AUTOSAR XML (schema 4-2-1)
package /RootP_IntDcm
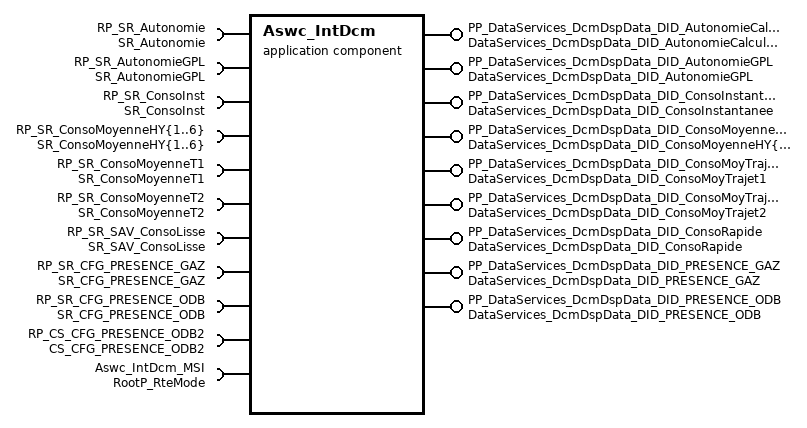
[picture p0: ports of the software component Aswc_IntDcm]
  application sw component type Aswc_IntDcm
    14 x provide port:
      PP_DataServices_DcmDspData_DID_AutonomieCalculee: server-com-spec{operation=DataServices_DcmDspData_DID_AutonomieCalculee/ReadData, queue-length=1}, provided-interface=DataServices_DcmDspData_DID_AutonomieCalculee
      PP_DataServices_DcmDspData_DID_AutonomieGPL: server-com-spec{operation=DataServices_DcmDspData_DID_AutonomieGPL/ReadData, queue-length=1}, provided-interface=DataServices_DcmDspData_DID_AutonomieGPL
      PP_DataServices_DcmDspData_DID_ConsoInstantanee: server-com-spec{operation=DataServices_DcmDspData_DID_ConsoInstantanee/ReadData, queue-length=1}, provided-interface=DataServices_DcmDspData_DID_ConsoInstantanee
      PP_DataServices_DcmDspData_DID_ConsoMoyenneHY{1..6}: server-com-spec{operation=DataServices_DcmDspData_DID_ConsoMoyenneHY{1..6}/ReadData, queue-length=1}, provided-interface=DataServices_DcmDspData_DID_ConsoMoyenneHY{1..6}
      PP_DataServices_DcmDspData_DID_ConsoMoyTrajet1: server-com-spec{operation=DataServices_DcmDspData_DID_ConsoMoyTrajet1/ReadData, queue-length=1}, provided-interface=DataServices_DcmDspData_DID_ConsoMoyTrajet1
      PP_DataServices_DcmDspData_DID_ConsoMoyTrajet2: server-com-spec{operation=DataServices_DcmDspData_DID_ConsoMoyTrajet2/ReadData, queue-length=1}, provided-interface=DataServices_DcmDspData_DID_ConsoMoyTrajet2
      PP_DataServices_DcmDspData_DID_ConsoRapide: server-com-spec{operation=DataServices_DcmDspData_DID_ConsoRapide/ReadData, queue-length=1}, provided-interface=DataServices_DcmDspData_DID_ConsoRapide
      PP_DataServices_DcmDspData_DID_PRESENCE_GAZ: provided-interface=DataServices_DcmDspData_DID_PRESENCE_GAZ
        provided-com-specs:
          operation=DataServices_DcmDspData_DID_PRESENCE_GAZ/ReadData, queue-length=1
          operation=DataServices_DcmDspData_DID_PRESENCE_GAZ/WriteData, queue-length=1
      PP_DataServices_DcmDspData_DID_PRESENCE_ODB: provided-interface=DataServices_DcmDspData_DID_PRESENCE_ODB
        provided-com-specs:
          operation=DataServices_DcmDspData_DID_PRESENCE_ODB/ReadData, queue-length=1
          operation=DataServices_DcmDspData_DID_PRESENCE_ODB/WriteData, queue-length=1
    provide/require port PP_SR_CFG_PRESENCE_GAZ: provided-required-interface=SR_CFG_PRESENCE_GAZ
    provide/require port PP_SR_CFG_PRESENCE_ODB: provided-required-interface=SR_CFG_PRESENCE_ODB
    16 x require port:
      RP_SR_Autonomie: required-interface=SR_Autonomie
      RP_SR_AutonomieGPL: required-interface=SR_AutonomieGPL
      RP_SR_ConsoInst: required-interface=SR_ConsoInst
      RP_SR_ConsoMoyenneHY{1..6}: required-interface=SR_ConsoMoyenneHY{1..6}
      RP_SR_ConsoMoyenneT1: required-interface=SR_ConsoMoyenneT1
      RP_SR_ConsoMoyenneT2: required-interface=SR_ConsoMoyenneT2
      RP_SR_SAV_ConsoLisse: required-interface=SR_SAV_ConsoLisse
      RP_SR_CFG_PRESENCE_GAZ: required-interface=SR_CFG_PRESENCE_GAZ
      RP_SR_CFG_PRESENCE_ODB: required-interface=SR_CFG_PRESENCE_ODB
      RP_CS_CFG_PRESENCE_ODB2: required-interface=CS_CFG_PRESENCE_ODB2
      Aswc_IntDcm_MSI: required-interface=RootP_RteMode
    behavior IB_Aswc_IntDcm: data-type-mapping=ApplicationModeMapping, handle-termination-and-restart=NO-SUPPORT
      16 x operation invoked event:
        DataServices_DcmDspData_DID_AutonomieCalculee_ReadData_OIE: start-on-event=RUNS_DID_AutonomieCalculee_Get, operation=PP_DataServices_DcmDspData_DID_AutonomieCalculee.ReadData
        DataServices_DcmDspData_DID_AutonomieGPL_ReadData_OIE: start-on-event=RUNS_DID_AutonomieGPL_Get, operation=PP_DataServices_DcmDspData_DID_AutonomieGPL.ReadData
        DataServices_DcmDspData_DID_ConsoInstantanee_ReadData_OIE: start-on-event=RUNS_DID_ConsoInstantanee_Get, operation=PP_DataServices_DcmDspData_DID_ConsoInstantanee.ReadData
        DataServices_DcmDspData_DID_ConsoMoyenneHY{1..6}_ReadData_OIE: start-on-event=RUNS_DID_ConsoMoyenneHY{1..6}_Get, operation=PP_DataServices_DcmDspData_DID_ConsoMoyenneHY{1..6}.ReadData
        DataServices_DcmDspData_DID_ConsoMoyTrajet1_ReadData_OIE: start-on-event=RUNS_DID_ConsoMoyTrajet1_Get, operation=PP_DataServices_DcmDspData_DID_ConsoMoyTrajet1.ReadData
        DataServices_DcmDspData_DID_ConsoMoyTrajet2_ReadData_OIE: start-on-event=RUNS_DID_ConsoMoyTrajet2_Get, operation=PP_DataServices_DcmDspData_DID_ConsoMoyTrajet2.ReadData
        DataServices_DcmDspData_DID_ConsoRapide_ReadData_OIE: start-on-event=RUNS_DID_ConsoRapide_Get, operation=PP_DataServices_DcmDspData_DID_ConsoRapide.ReadData
        DataServices_DcmDspData_DID_PRESENCE_GAZ_ReadData_OIE: start-on-event=RUNS_DID_PRESENCE_GAZ_Get, operation=PP_DataServices_DcmDspData_DID_PRESENCE_GAZ.ReadData
        DataServices_DcmDspData_DID_PRESENCE_GAZ_WriteData_OIE: start-on-event=RUNS_DID_PRESENCE_GAZ_Set, operation=PP_DataServices_DcmDspData_DID_PRESENCE_GAZ.WriteData
        DataServices_DcmDspData_DID_PRESENCE_ODB_ReadData_OIE: start-on-event=RUNS_DID_PRESENCE_ODB_Get, operation=PP_DataServices_DcmDspData_DID_PRESENCE_ODB.ReadData
        DataServices_DcmDspData_DID_PRESENCE_ODB_WriteData_OIE: start-on-event=RUNS_DID_PRESENCE_ODB_Set, operation=PP_DataServices_DcmDspData_DID_PRESENCE_ODB.WriteData
      swc mode switch event RUNPI_Aswc_IntDcm_ENTRY: start-on-event=RUNPI_Aswc_IntDcm, activation=ON-ENTRY, mode=Aswc_IntDcm_MSI.RteMode.APP_WAKEUP
      17 x runnable:
        RUNS_DID_AutonomieCalculee_Get
          data-read-access:
            access dra_Autonomie: accessed-variable=RP_SR_Autonomie.Autonomie
        RUNS_DID_AutonomieGPL_Get
          data-read-access:
            access dra_Autonomie: accessed-variable=RP_SR_Autonomie.Autonomie
            access dra_AutonomieGPL: accessed-variable=RP_SR_AutonomieGPL.AutonomieGPL
        RUNS_DID_ConsoInstantanee_Get
          data-read-access:
            access dra_Autonomie: accessed-variable=RP_SR_Autonomie.Autonomie
            access dra_AutonomieGPL: accessed-variable=RP_SR_AutonomieGPL.AutonomieGPL
            access dra_ConsoInst: accessed-variable=RP_SR_ConsoInst.ConsoInst
        RUNS_DID_ConsoMoyenneHY1_Get
          data-read-access:
            4 x access:
              dra_Autonomie: accessed-variable=RP_SR_Autonomie.Autonomie
              dra_AutonomieGPL: accessed-variable=RP_SR_AutonomieGPL.AutonomieGPL
              dra_ConsoInst: accessed-variable=RP_SR_ConsoInst.ConsoInst
              dra_ConsoMoyenneHY1: accessed-variable=RP_SR_ConsoMoyenneHY1.ConsoMoyenneHY1
        RUNS_DID_ConsoMoyenneHY2_Get
          data-read-access:
            5 x access:
              dra_Autonomie: accessed-variable=RP_SR_Autonomie.Autonomie
              dra_AutonomieGPL: accessed-variable=RP_SR_AutonomieGPL.AutonomieGPL
              dra_ConsoInst: accessed-variable=RP_SR_ConsoInst.ConsoInst
              dra_ConsoMoyenneHY1: accessed-variable=RP_SR_ConsoMoyenneHY1.ConsoMoyenneHY1
              dra_ConsoMoyenneHY2: accessed-variable=RP_SR_ConsoMoyenneHY2.ConsoMoyenneHY2
        RUNS_DID_ConsoMoyenneHY3_Get
          data-read-access:
            6 x access:
              dra_Autonomie: accessed-variable=RP_SR_Autonomie.Autonomie
              dra_AutonomieGPL: accessed-variable=RP_SR_AutonomieGPL.AutonomieGPL
              dra_ConsoInst: accessed-variable=RP_SR_ConsoInst.ConsoInst
              dra_ConsoMoyenneHY{1..3}: accessed-variable=RP_SR_ConsoMoyenneHY{1..3}.ConsoMoyenneHY{1..3}
        RUNS_DID_ConsoMoyenneHY4_Get
          data-read-access:
            7 x access:
              dra_Autonomie: accessed-variable=RP_SR_Autonomie.Autonomie
              dra_AutonomieGPL: accessed-variable=RP_SR_AutonomieGPL.AutonomieGPL
              dra_ConsoInst: accessed-variable=RP_SR_ConsoInst.ConsoInst
              dra_ConsoMoyenneHY{1..4}: accessed-variable=RP_SR_ConsoMoyenneHY{1..4}.ConsoMoyenneHY{1..4}
        RUNS_DID_ConsoMoyenneHY5_Get
          data-read-access:
            8 x access:
              dra_Autonomie: accessed-variable=RP_SR_Autonomie.Autonomie
              dra_AutonomieGPL: accessed-variable=RP_SR_AutonomieGPL.AutonomieGPL
              dra_ConsoInst: accessed-variable=RP_SR_ConsoInst.ConsoInst
              dra_ConsoMoyenneHY{1..5}: accessed-variable=RP_SR_ConsoMoyenneHY{1..5}.ConsoMoyenneHY{1..5}
        RUNS_DID_ConsoMoyenneHY6_Get
          data-read-access:
            9 x access:
              dra_Autonomie: accessed-variable=RP_SR_Autonomie.Autonomie
              dra_AutonomieGPL: accessed-variable=RP_SR_AutonomieGPL.AutonomieGPL
              dra_ConsoInst: accessed-variable=RP_SR_ConsoInst.ConsoInst
              dra_ConsoMoyenneHY{1..6}: accessed-variable=RP_SR_ConsoMoyenneHY{1..6}.ConsoMoyenneHY{1..6}
        RUNS_DID_ConsoMoyTrajet1_Get
          data-read-access:
            10 x access:
              dra_Autonomie: accessed-variable=RP_SR_Autonomie.Autonomie
              dra_AutonomieGPL: accessed-variable=RP_SR_AutonomieGPL.AutonomieGPL
              dra_ConsoInst: accessed-variable=RP_SR_ConsoInst.ConsoInst
              dra_ConsoMoyenneHY{1..6}: accessed-variable=RP_SR_ConsoMoyenneHY{1..6}.ConsoMoyenneHY{1..6}
              dra_ConsoMoyenneT1: accessed-variable=RP_SR_ConsoMoyenneT1.ConsoMoyenneT1
        RUNS_DID_ConsoMoyTrajet2_Get
          data-read-access:
            11 x access:
              dra_Autonomie: accessed-variable=RP_SR_Autonomie.Autonomie
              dra_AutonomieGPL: accessed-variable=RP_SR_AutonomieGPL.AutonomieGPL
              dra_ConsoInst: accessed-variable=RP_SR_ConsoInst.ConsoInst
              dra_ConsoMoyenneHY{1..6}: accessed-variable=RP_SR_ConsoMoyenneHY{1..6}.ConsoMoyenneHY{1..6}
              dra_ConsoMoyenneT1: accessed-variable=RP_SR_ConsoMoyenneT1.ConsoMoyenneT1
              dra_ConsoMoyenneT2: accessed-variable=RP_SR_ConsoMoyenneT2.ConsoMoyenneT2
        RUNS_DID_ConsoRapide_Get
          data-read-access:
            12 x access:
              dra_Autonomie: accessed-variable=RP_SR_Autonomie.Autonomie
              dra_AutonomieGPL: accessed-variable=RP_SR_AutonomieGPL.AutonomieGPL
              dra_ConsoInst: accessed-variable=RP_SR_ConsoInst.ConsoInst
              dra_ConsoMoyenneHY{1..6}: accessed-variable=RP_SR_ConsoMoyenneHY{1..6}.ConsoMoyenneHY{1..6}
              dra_ConsoMoyenneT1: accessed-variable=RP_SR_ConsoMoyenneT1.ConsoMoyenneT1
              dra_ConsoMoyenneT2: accessed-variable=RP_SR_ConsoMoyenneT2.ConsoMoyenneT2
              dra_SAV_ConsoLisse: accessed-variable=RP_SR_SAV_ConsoLisse.SAV_ConsoLisse
        RUNS_DID_PRESENCE_GAZ_Get
          data-read-access:
            13 x access:
              dra_Autonomie: accessed-variable=RP_SR_Autonomie.Autonomie
              dra_AutonomieGPL: accessed-variable=RP_SR_AutonomieGPL.AutonomieGPL
              dra_ConsoInst: accessed-variable=RP_SR_ConsoInst.ConsoInst
              dra_ConsoMoyenneHY{1..6}: accessed-variable=RP_SR_ConsoMoyenneHY{1..6}.ConsoMoyenneHY{1..6}
              dra_ConsoMoyenneT1: accessed-variable=RP_SR_ConsoMoyenneT1.ConsoMoyenneT1
              dra_ConsoMoyenneT2: accessed-variable=RP_SR_ConsoMoyenneT2.ConsoMoyenneT2
              dra_SAV_ConsoLisse: accessed-variable=RP_SR_SAV_ConsoLisse.SAV_ConsoLisse
              dra_CFG_PRESENCE_GAZ: accessed-variable=RP_SR_CFG_PRESENCE_GAZ.CFG_PRESENCE_GAZ
        RUNS_DID_PRESENCE_GAZ_Set
          data-read-access:
            access dra_CFG_PRESENCE_GAZ: accessed-variable=PP_SR_CFG_PRESENCE_GAZ.CFG_PRESENCE_GAZ
          data-write-access:
            access dwa_CFG_PRESENCE_GAZ: accessed-variable=PP_SR_CFG_PRESENCE_GAZ.CFG_PRESENCE_GAZ
        RUNS_DID_PRESENCE_ODB_Get
          data-read-access:
            14 x access:
              dra_Autonomie: accessed-variable=RP_SR_Autonomie.Autonomie
              dra_AutonomieGPL: accessed-variable=RP_SR_AutonomieGPL.AutonomieGPL
              dra_ConsoInst: accessed-variable=RP_SR_ConsoInst.ConsoInst
              dra_ConsoMoyenneHY{1..6}: accessed-variable=RP_SR_ConsoMoyenneHY{1..6}.ConsoMoyenneHY{1..6}
              dra_ConsoMoyenneT1: accessed-variable=RP_SR_ConsoMoyenneT1.ConsoMoyenneT1
              dra_ConsoMoyenneT2: accessed-variable=RP_SR_ConsoMoyenneT2.ConsoMoyenneT2
              dra_SAV_ConsoLisse: accessed-variable=RP_SR_SAV_ConsoLisse.SAV_ConsoLisse
              dra_CFG_PRESENCE_GAZ: accessed-variable=RP_SR_CFG_PRESENCE_GAZ.CFG_PRESENCE_GAZ
              dra_CFG_PRESENCE_ODB: accessed-variable=RP_SR_CFG_PRESENCE_ODB.CFG_PRESENCE_ODB
        RUNS_DID_PRESENCE_ODB_Set
          data-read-access:
            access dra_CFG_PRESENCE_GAZ: accessed-variable=PP_SR_CFG_PRESENCE_GAZ.CFG_PRESENCE_GAZ
            access dra_CFG_PRESENCE_ODB: accessed-variable=PP_SR_CFG_PRESENCE_ODB.CFG_PRESENCE_ODB
          data-write-access:
            access dwa_CFG_PRESENCE_GAZ: accessed-variable=PP_SR_CFG_PRESENCE_GAZ.CFG_PRESENCE_GAZ
            access dwa_CFG_PRESENCE_ODB: accessed-variable=PP_SR_CFG_PRESENCE_ODB.CFG_PRESENCE_ODB
        RUNPI_Aswc_IntDcm
package /AUTOSAR_Dcm/PortInterfaces
  14 x client server interface, all with is-service=true:
    DataServices_DcmDspData_DID_AutonomieCalculee
      operation ReadData
        arg Data: type=tBYTE, direction=OUT
    DataServices_DcmDspData_DID_AutonomieGPL
      operation ReadData
        arg Data: type=tBYTE, direction=OUT
    DataServices_DcmDspData_DID_ConsoInstantanee
      operation ReadData
        arg Data: type=tBYTE, direction=OUT
    DataServices_DcmDspData_DID_ConsoMoyenneHY1
      operation ReadData
        arg Data: type=tBYTE, direction=OUT
    DataServices_DcmDspData_DID_ConsoMoyenneHY2
      operation ReadData
        arg Data: type=tBYTE, direction=OUT
    DataServices_DcmDspData_DID_ConsoMoyenneHY3
      operation ReadData
        arg Data: type=tBYTE, direction=OUT
    DataServices_DcmDspData_DID_ConsoMoyenneHY4
      operation ReadData
        arg Data: type=tBYTE, direction=OUT
    DataServices_DcmDspData_DID_ConsoMoyenneHY5
      operation ReadData
        arg Data: type=tBYTE, direction=OUT
    DataServices_DcmDspData_DID_ConsoMoyenneHY6
      operation ReadData
        arg Data: type=tBYTE, direction=OUT
    DataServices_DcmDspData_DID_ConsoMoyTrajet1
      operation ReadData
        arg Data: type=tBYTE, direction=OUT
    DataServices_DcmDspData_DID_ConsoMoyTrajet2
      operation ReadData
        arg Data: type=tBYTE, direction=OUT
    DataServices_DcmDspData_DID_ConsoRapide
      operation ReadData
        arg Data: type=tBYTE, direction=OUT
    DataServices_DcmDspData_DID_PRESENCE_GAZ
      operation ReadData
        arg Data: type=tBYTE, direction=OUT
      operation WriteData
        arg Data: type=tBYTE, direction=IN
        arg ErrorCode: type=tBYTE, direction=OUT
    DataServices_DcmDspData_DID_PRESENCE_ODB
      operation ReadData
        arg Data: type=tBYTE, direction=OUT
      operation WriteData
        arg Data: type=tBYTE, direction=IN
        arg ErrorCode: type=tBYTE, direction=OUT
